# CPSW_CPSW3_08000000h register map
Vendor: Texas Instruments
Registers are 32-bit, read-write, reset 0x0 unless marked. A register's access mark holds for its fields unless they carry their own. Offsets are as the file gives them; [hi:lo] are bit positions; {n}, {i} and the like mark numbered series; 'fields as' and 'values as' point back to an identical list.

## cpsw3 (part 3 of 5)
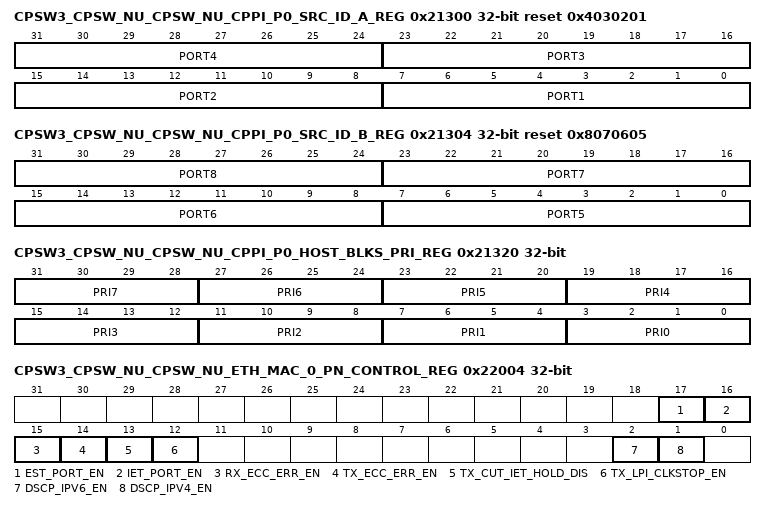
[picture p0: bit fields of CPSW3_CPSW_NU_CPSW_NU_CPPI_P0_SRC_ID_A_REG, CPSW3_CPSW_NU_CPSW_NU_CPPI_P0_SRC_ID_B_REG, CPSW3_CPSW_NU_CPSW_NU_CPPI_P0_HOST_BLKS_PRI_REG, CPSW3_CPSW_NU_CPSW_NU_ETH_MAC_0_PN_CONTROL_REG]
0x21300 CPSW3_CPSW_NU_CPSW_NU_CPPI_P0_SRC_ID_A_REG reset 0x4030201 — CPPI Port 0 CPPI Source ID A
  [8n-1:8n-8] PORT{n} (n=1..4) — Port {n} CPPI Info Word0 Source ID Value. This value is contained in the CPPI Info Word 0 SRC_ID field for packets received on port {n}.
0x21304 CPSW3_CPSW_NU_CPSW_NU_CPPI_P0_SRC_ID_B_REG reset 0x8070605 — CPPI Port 0 CPPI Source ID B
  [8n-33:8n-40] PORT{n} (n=5..8) — Port {n} CPPI Info Word0 Source ID Value. This value is contained in the CPPI Info Word 0 SRC_ID field for packets received on port {n}.
0x21320 CPSW3_CPSW_NU_CPSW_NU_CPPI_P0_HOST_BLKS_PRI_REG — CPPI Port 0 Host Blocks Priority
  [4n+3:4n] PRI{n} (n=0..7) — Priority {n} Host Blocks
0x22000 CPSW3_CPSW_NU_CPSW_NU_ETH_MAC_0_PN_RESERVED_REG ro — Reserved
0x22004 CPSW3_CPSW_NU_CPSW_NU_ETH_MAC_0_PN_CONTROL_REG — Enet Port N Control
  [17] EST_PORT_EN — EST Port Enable. 0h EST is disabled on the port1h EST is enabled on the port - Does not take effect until CPSW_CONTROL_REG[18] EST_ENABLE is set.
  [16] IET_PORT_EN — Intersperced Express Traffic (IET) Port Enable. 0h IET is disabled on the port1h IET is enabled on the port - Does not take effect until CPSW_CONTROL_REG[18] EST_ENABLE is set.
  [15] RX_ECC_ERR_EN — Port N receive ECC Error Enable. This bit must be set to enable receive ECC error operations
  [14] TX_ECC_ERR_EN — Port N transmit ECC Error Enable. This bit must be set to enable transmit ECC error operations
  [13] TX_CUT_IET_HOLD_DIS — Port N transmit IET hold due to cut-thru disable 0h Cut-thru packets to the port will cause premptable traffic to be prempted as early as possible minimizing cut-thru latency1h Cut-thru packets to the port will be prempted as usual by the express MAC
  [12] TX_LPI_CLKSTOP_EN — Transmit LPI Clock Stop Enable. When set this bit causes the transmit output clock (GMII_GMTCLK_O) to be stopped when the transmit LPI state is entered if EEE is enabled.
  [2] DSCP_IPV6_EN — IPV6 DSCP enable 0h IPV6 DSCP priority mapping is disabled1h IPV6 DSCP priority mapping is enabled
  [1] DSCP_IPV4_EN — IPV4 DSCP enable 0h IPV4 DSCP priority mapping is disabled1h IPV4 DSCP priority mapping is enabled
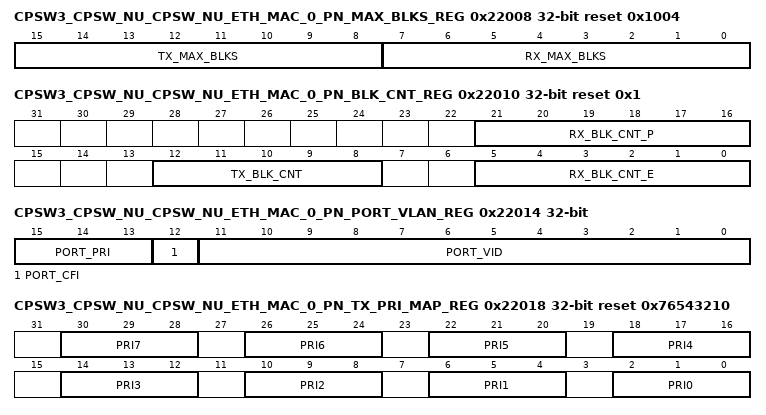
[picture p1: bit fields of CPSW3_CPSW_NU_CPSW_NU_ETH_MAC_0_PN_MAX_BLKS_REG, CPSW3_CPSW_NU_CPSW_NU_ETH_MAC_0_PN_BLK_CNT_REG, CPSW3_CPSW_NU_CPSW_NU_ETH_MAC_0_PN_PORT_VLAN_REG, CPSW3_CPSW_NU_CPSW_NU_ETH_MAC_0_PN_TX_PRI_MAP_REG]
0x22008 CPSW3_CPSW_NU_CPSW_NU_ETH_MAC_0_PN_MAX_BLKS_REG reset 0x1004 — Enet Port N FIFO Max Blocks
  [15:8] TX_MAX_BLKS — Transmit Max Blocks. The maximum number of blocks allowed on all transmit FIFO priorities combined. If (fifo_oneram = 1) then blocks should be moved from transmit to receive, when Fullduplex flow control is enabled (CPSW_PN_MAC_CONTROL_REG_k[0] FULLDUPLEX = 1h) to allow for flow control runout.
  [7:0] RX_MAX_BLKS — Receive Max Blocks. The maximum number of blocks allowed on the express and prempt receive FIFOs (transmit and receive FIFO's combined when fifo_oneram = 1)
0x22010 CPSW3_CPSW_NU_CPSW_NU_ETH_MAC_0_PN_BLK_CNT_REG ro reset 0x1 — Enet Port N FIFO Block Usage Count
  [21:16] RX_BLK_CNT_P — Receive Express Block Count Usage. This value is the number of blocks allocated to the port's FIFO prempt receive queue. No blocks are allocated until the CPSW_CONTROL_REG[17] IET_ENABLE is set.
  [12:8] TX_BLK_CNT — Transmit Block Count Usage. This value is the number of blocks allocated to the port's FIFO logical transmit queues.
  [5:0] RX_BLK_CNT_E — Receive Express Block Count Usage. This value is the number of blocks allocated to the port's FIFO express receive queue.
0x22014 CPSW3_CPSW_NU_CPSW_NU_ETH_MAC_0_PN_PORT_VLAN_REG — Enet Port N VLAN
  [15:13] PORT_PRI — Port VLAN Priority
  [12] PORT_CFI — Port CFI bit
  [11:0] PORT_VID — Port VLAN ID
0x22018 CPSW3_CPSW_NU_CPSW_NU_ETH_MAC_0_PN_TX_PRI_MAP_REG reset 0x76543210 — Enet Port N Tx Header Pri to Switch Pri Mapping
  [4n+2:4n] PRI{n} (n=0..7) — Priority {n}. A packet header priority of {n}h is given this switch queue pri.
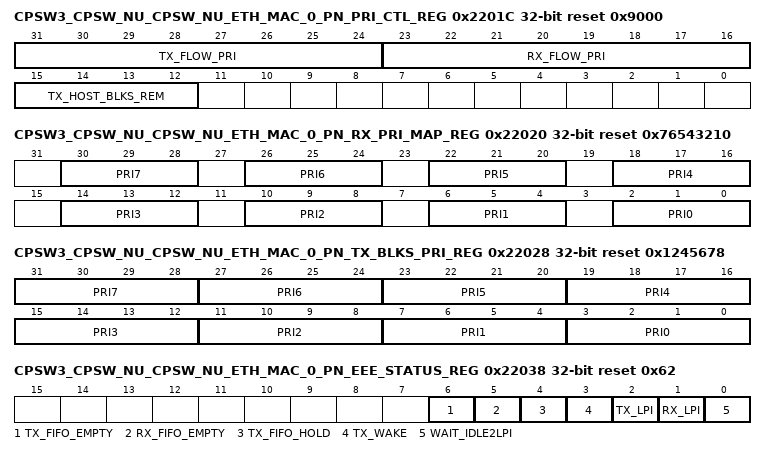
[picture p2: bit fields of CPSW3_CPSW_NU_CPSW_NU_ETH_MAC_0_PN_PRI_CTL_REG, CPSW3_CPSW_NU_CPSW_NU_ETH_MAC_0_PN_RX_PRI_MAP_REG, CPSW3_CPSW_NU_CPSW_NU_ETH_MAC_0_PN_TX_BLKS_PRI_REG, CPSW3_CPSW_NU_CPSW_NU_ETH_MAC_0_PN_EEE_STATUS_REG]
0x2201C CPSW3_CPSW_NU_CPSW_NU_ETH_MAC_0_PN_PRI_CTL_REG reset 0x9000 — Enet Port N Priority Control
  [31:24] TX_FLOW_PRI — Transmit Priority Based Flow Control Enable (per priority)
  [23:16] RX_FLOW_PRI — Receive Priority Based Flow Control Enable (per priority)
  [15:12] TX_HOST_BLKS_REM — Transmit FIFO Blocks that must be free before a non rate-limited CPPI Port 0 receive thread can begin sending a packet
0x22020 CPSW3_CPSW_NU_CPSW_NU_ETH_MAC_0_PN_RX_PRI_MAP_REG reset 0x76543210 — Enet Port N RX Pkt Pri to Header Pri Map
  [4n+2:4n] PRI{n} (n=0..7) — Priority {n}. A packet pri of {n}h is mapped (changed) to this header packet pri.
0x22024 CPSW3_CPSW_NU_CPSW_NU_ETH_MAC_0_PN_RX_MAXLEN_REG reset 0x5EE — Enet Port N Receive Frame Max Length
  [13:0] RX_MAXLEN — RX Maximum Frame Length. This field determines the maximum length of a received frame. The reset value is 1518 (dec). Frames with byte counts greater than the value in CPSW_PN_RX_MAXLEN_REG_k[13-0] RX_MAXLEN are long frames. Long frames with no errors are oversized frames. Long frames with CRC, code, or alignment error are jabber frames. The maximum value is 9604 (including VLAN).
0x22028 CPSW3_CPSW_NU_CPSW_NU_ETH_MAC_0_PN_TX_BLKS_PRI_REG reset 0x1245678 — Enet Port N Transmit Block Sub Per Priority
  [4n+3:4n] PRI{n} (n=0..7) — Priority {n} Port Transmit Blocks
0x22030 CPSW3_CPSW_NU_CPSW_NU_ETH_MAC_0_PN_IDLE2LPI_REG — Enet Port N EEE Idle to LPI counter
  [23:0] COUNT — EEE Idle to LPI counter load value
0x22034 CPSW3_CPSW_NU_CPSW_NU_ETH_MAC_0_PN_LPI2WAKE_REG — Enet Port N EEE LPI to wake counter
  [23:0] COUNT — EEE LPI to wake counter load value
0x22038 CPSW3_CPSW_NU_CPSW_NU_ETH_MAC_0_PN_EEE_STATUS_REG ro reset 0x62 — Enet Port N EEE status
  [6] TX_FIFO_EMPTY — Transmit FIFO (switch egress) is empty - contains no packets
  [5] RX_FIFO_EMPTY — Receive FIFO (switch ingress) is empty - contains no packets
  [4] TX_FIFO_HOLD — Transmit FIFO hold - asserted in the LPI state and during the LPI2WAKE count time
  [3] TX_WAKE — Transmit wakeup - asserted in the transmit LPI2WAKE count time
  [2] TX_LPI — Transmit LPI state - asserted when the port 0 transmit is in the LPI state
  [1] RX_LPI — Receive LPI state - asserted when the port 0 receive is in the LPI state
  [0] WAIT_IDLE2LPI — CPPI port 0 wait idle to LPI - asserted when port 0 is counting the IDLE2LPI time
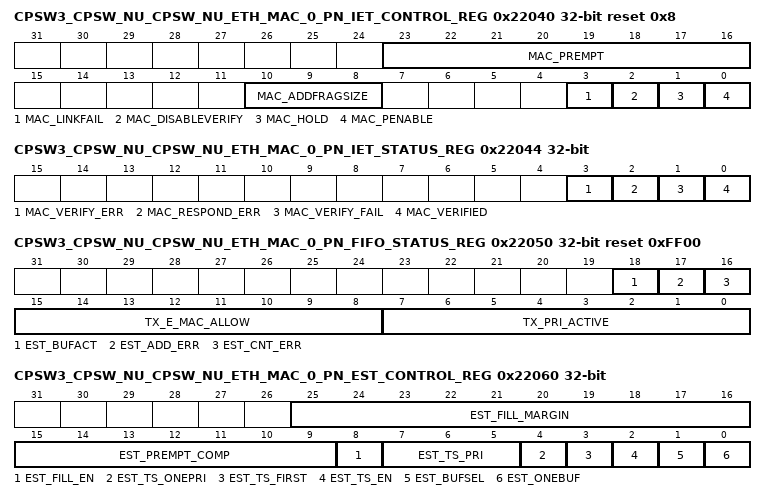
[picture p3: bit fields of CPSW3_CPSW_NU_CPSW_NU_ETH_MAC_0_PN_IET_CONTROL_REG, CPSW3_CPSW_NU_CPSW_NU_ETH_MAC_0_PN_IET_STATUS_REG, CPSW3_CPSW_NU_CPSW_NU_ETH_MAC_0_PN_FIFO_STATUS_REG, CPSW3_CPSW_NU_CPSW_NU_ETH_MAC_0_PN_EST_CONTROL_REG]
0x22040 CPSW3_CPSW_NU_CPSW_NU_ETH_MAC_0_PN_IET_CONTROL_REG reset 0x8 — Enet Port N IET Control
  [23:16] MAC_PREMPT — Mac Preempt Queue - Indicates which transmit FIFO queues are sent to the preempt MAC. Bit 0 indicates queue zero, bit 1 queue 1 and so on. Packets will be sent to the preempt MAC only when MAC_PENABLE is set, and when MAC_VERIFIED (from CPSW_PN_IET_STATUS_REG_k) or MAC_DISABLEVERIFY is set, and when IET_PORT_EN is set.
  [10:8] MAC_ADDFRAGSIZE — Mac Fragment Size - An integer in the range 0:7 indicating, as a multiple of 64, the minimum additional length for nonfinal mPackets. 0 641 1282 813 2564 3205 3846 4487 512
  [3] MAC_LINKFAIL — Mac Link Fail - Link Fail Indicator to reset the verify state machine. This bit is reset high. Verify and response frames will be sent/allowed when this bit is cleared.
  [2] MAC_DISABLEVERIFY — Mac Disable Verify - Disables verification on the port when set. If this bit is set then packets will be sent to the preempt Mac when MAC_PENABLE is set (This is a forced mode with no IET verification).
  [1] MAC_HOLD — Mac Hold - Hold Preemption on the port.
  [0] MAC_PENABLE — Mac Preemption Enable - Port Preemption Enable. This takes effect only when IET_PORT_EN is set.
0x22044 CPSW3_CPSW_NU_CPSW_NU_ETH_MAC_0_PN_IET_STATUS_REG ro — Enet Port N IET Status
  [3] MAC_VERIFY_ERR — Mac Received Verify Packet with Errors - Set when a verify packet with errors is received. Cleared when MAC_PENABLE is cleared to zero.
  [2] MAC_RESPOND_ERR — Mac Received Respond Packet with Errors - Set when a respond packet with errors is received. Cleared when MAC_PENABLE is cleared to zero.
  [1] MAC_VERIFY_FAIL — Mac Verification Failed - Indication that verification was unsuccessful.
  [0] MAC_VERIFIED — Mac Verified - Indication that verification was successful.
0x22048 CPSW3_CPSW_NU_CPSW_NU_ETH_MAC_0_PN_IET_VERIFY_REG reset 0x1312D0 — Enet Port N IET VERIFY
  [23:0] MAC_VERIFY_CNT — Mac Verify Timeout Count - The number of wireside clocks contained in the verify timeout counter. The default is 0x1312D0 (10ms at 125MHz in gig mode).
0x22050 CPSW3_CPSW_NU_CPSW_NU_ETH_MAC_0_PN_FIFO_STATUS_REG ro reset 0xFF00 — Enet Port N FIFO STATUS
  [18] EST_BUFACT — EST RAM active buffer. Indicates the active 64-word fetch buffer when CPSW_PN_EST_CONTROL_REG_k[0] EST_ONEBUF is cleared to zero. Indicates the fetch RAM address MSB when bit [0] EST_ONEBUF is set to one.
  [17] EST_ADD_ERR — EST Address Error. Indicates that the fetch RAM was read again after the previous maximum buffer address read (the previous fetch from the maximum address is reused).
  [16] EST_CNT_ERR — EST Fetch Count Error. Indicates that insufficient clocks were programmed into the fetch count and that another fetch was commanded before the previous fetch finished.
  [15:8] TX_E_MAC_ALLOW — EST transmit MAC allow. Bus that indicates the actual priorities assigned to the express queue (and inversely the priorities assigned to the prempt queue).
  [7:0] TX_PRI_ACTIVE — EST Transmit Priority Active. Bus that indicates which priorities have packets (non-empty) at the time of the register read.
0x22060 CPSW3_CPSW_NU_CPSW_NU_ETH_MAC_0_PN_EST_CONTROL_REG — Enet Port N EST CONTROL
  [25:16] EST_FILL_MARGIN — EST Fill Margin. Sets the fill margin required to ensure that the Ethernet wire is clear (including IPG) so that the timed EST express packet can egress at the required time. Setting this value too high will put an unnecessary gap on the wire. Setting this value too low will cause the express packet to egress at a time later than intended.
  [15:9] EST_PREMPT_COMP — EST Prempt Comparison Value. When the count in a zero allow is less than or equal to this value in bytes (times 8), prempt packets are cleared from the wire. This is the prempt clear margin value.
  [8] EST_FILL_EN — EST Fill Enable. Enable EST fill mode.
  [7:5] EST_TS_PRI — EST Timestamp Express Priority. Selects the express priority that timestamp(s) will be generated on when CPSW_PN_EST_CONTROL_REG_k[4] EST_TS_ONEPRI bit is set.
  [4] EST_TS_ONEPRI — EST Timestamp One Express Priority. When set, timestamp only enabled packets on the express priority selected by CPSW_PN_EST_CONTROL_REG_k[7-5] ST_TS_PRI bit field. When cleared to zero, express packet selection for timestamp is independent of priority.
  [3] EST_TS_FIRST — EST Timestamp First Express Packet only. Generate a timestamp only on the first selected express packet in each EST time interval when express timestamps are enabled. (If CPSW_PN_EST_CONTROL_REG_k[4] EST_TS_ONEPRI is also set then the timestamp is generated only on the first packet on CPSW_PN_EST_CONTROL_REG_k[7-5] ST_TS_PRI).
  [2] EST_TS_EN — EST Timestamp Enable. Enable express timestamps (when CPSW_CONTROL_REG[18] EST_ENABLE and CPSW_PN_CONTROL_REG_k[17] EST_PORT_EN bits are set).
  [1] EST_BUFSEL — EST Buffer Select. If CPSW_PN_EST_CONTROL_REG_k[0] EST_ONEBUF is cleared, this bit selects the upper (when set) or the lower (when cleared) 64-word fetch buffer. The actual fetch buffer used changes only at the start of the EST time interval and can be read in the CPSW_PN_FIFO_STATUS_REG_k register, bit [18] EST_BUFACT.
  [0] EST_ONEBUF — EST One Fetch Buffer. When set indicates that all 128 fetch words are used in one buffer. When cleared, indicates that the 128 fetch words are split into two 64-word fetch buffers. The CPSW_PN_EST_CONTROL_REG_k[1] EST_BUFSEL bit selects the buffer to be used when bit [0] EST_ONEBUF is cleared to zero.
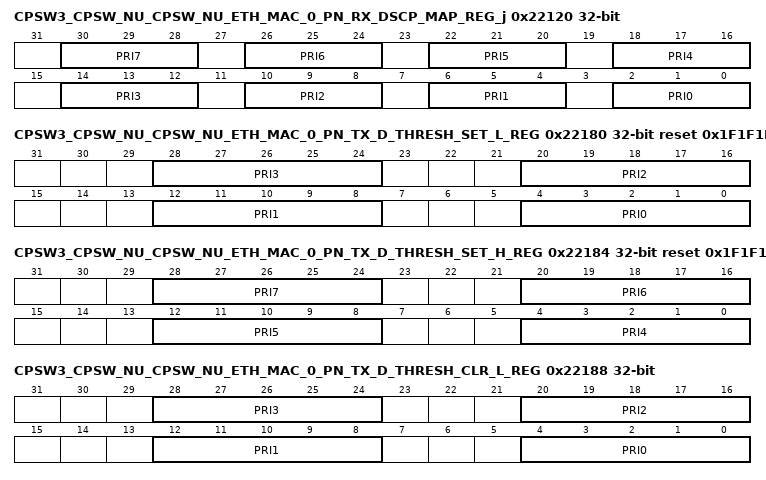
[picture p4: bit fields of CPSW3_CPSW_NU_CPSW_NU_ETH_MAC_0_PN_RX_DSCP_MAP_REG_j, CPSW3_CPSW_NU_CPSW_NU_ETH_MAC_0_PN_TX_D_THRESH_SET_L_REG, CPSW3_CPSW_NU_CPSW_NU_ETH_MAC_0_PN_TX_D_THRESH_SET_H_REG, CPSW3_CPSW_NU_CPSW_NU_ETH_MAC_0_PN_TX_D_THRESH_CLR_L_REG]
0x22120 CPSW3_CPSW_NU_CPSW_NU_ETH_MAC_0_PN_RX_DSCP_MAP_REG_j — Enet Port N Receive IPV4/IPV6 DSCP Map M
  [4n+2:4n] PRI{n} (n=0..7) — A DSCP IPV4/V6 packet TOS of N*8+{n} is mapped to this received priority
0x22140 CPSW3_CPSW_NU_CPSW_NU_ETH_MAC_0_PN_PRI_CIR_REG_j — Enet Port N Rx Priority P Committed Information Rate Value
  [27:0] PRI_CIR — Priority N committed information rate
0x22160 CPSW3_CPSW_NU_CPSW_NU_ETH_MAC_0_PN_PRI_EIR_REG_j — Enet Port N Rx Priority P Excess Informatoin Rate Value
  [27:0] PRI_EIR — Priority N Excess Information Rate count
0x22180 CPSW3_CPSW_NU_CPSW_NU_ETH_MAC_0_PN_TX_D_THRESH_SET_L_REG reset 0x1F1F1F1F — Enet Port N Tx PFC Destination Threshold Set Low
  [8n+4:8n] PRI{n} (n=0..3) — Port Priority Based Flow Control Threshold Set Value for Priority {n}
0x22184 CPSW3_CPSW_NU_CPSW_NU_ETH_MAC_0_PN_TX_D_THRESH_SET_H_REG reset 0x1F1F1F1F — Enet Port N Tx PFC Destination Threshold Set High
  [8n-28:8n-32] PRI{n} (n=4..7) — Port Priority Based Flow Control Threshold Set Value for Priority {n}
0x22188 CPSW3_CPSW_NU_CPSW_NU_ETH_MAC_0_PN_TX_D_THRESH_CLR_L_REG — Enet Port N Tx PFC Destination Threshold Clr Low
  [8n+4:8n] PRI{n} (n=0..3) — Port Priority Based Flow Control Threshold Clear Value for Priority {n}
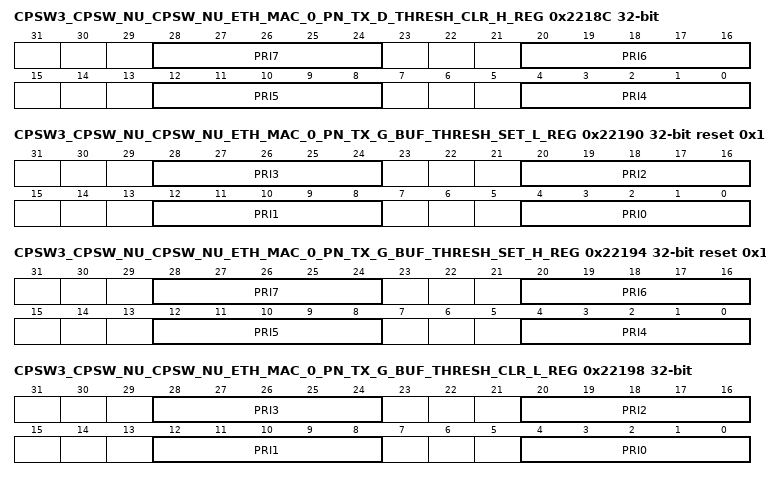
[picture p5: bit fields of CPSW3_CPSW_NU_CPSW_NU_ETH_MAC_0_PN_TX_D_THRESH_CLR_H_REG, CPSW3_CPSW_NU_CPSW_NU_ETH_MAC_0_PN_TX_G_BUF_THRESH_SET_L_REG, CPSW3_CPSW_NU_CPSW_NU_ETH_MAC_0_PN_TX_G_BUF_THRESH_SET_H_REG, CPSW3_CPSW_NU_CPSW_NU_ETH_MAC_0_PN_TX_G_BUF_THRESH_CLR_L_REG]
0x2218C CPSW3_CPSW_NU_CPSW_NU_ETH_MAC_0_PN_TX_D_THRESH_CLR_H_REG — Enet Port N Tx PFC Destination Threshold Clr High
  [8n-28:8n-32] PRI{n} (n=4..7) — Port Priority Based Flow Control Threshold Clear Value for Priority {n}
0x22190 CPSW3_CPSW_NU_CPSW_NU_ETH_MAC_0_PN_TX_G_BUF_THRESH_SET_L_REG reset 0x1F1F1F1F — Enet Port N Tx PFC Global Buffer Threshold Set Low
  fields as CPSW3_CPSW_NU_CPSW_NU_ETH_MAC_0_PN_TX_D_THRESH_SET_L_REG
0x22194 CPSW3_CPSW_NU_CPSW_NU_ETH_MAC_0_PN_TX_G_BUF_THRESH_SET_H_REG reset 0x1F1F1F1F — Enet Port N Tx PFC Global Buffer Threshold Set High
  fields as CPSW3_CPSW_NU_CPSW_NU_ETH_MAC_0_PN_TX_D_THRESH_SET_H_REG
0x22198 CPSW3_CPSW_NU_CPSW_NU_ETH_MAC_0_PN_TX_G_BUF_THRESH_CLR_L_REG — Enet Port N Tx PFC Global Buffer Threshold Clr Low
  fields as CPSW3_CPSW_NU_CPSW_NU_ETH_MAC_0_PN_TX_D_THRESH_CLR_L_REG
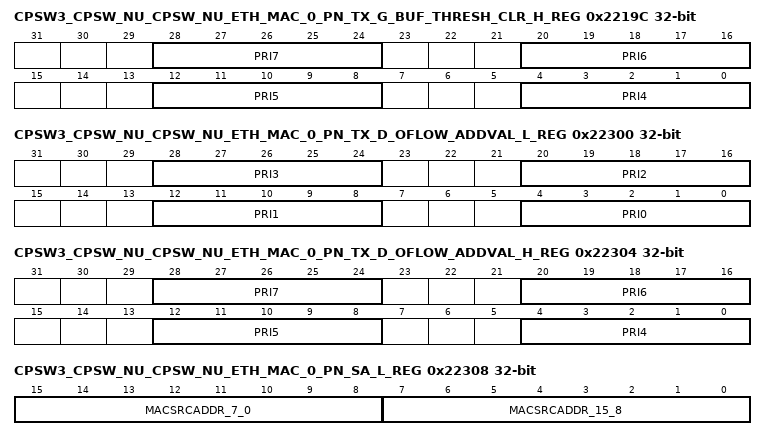
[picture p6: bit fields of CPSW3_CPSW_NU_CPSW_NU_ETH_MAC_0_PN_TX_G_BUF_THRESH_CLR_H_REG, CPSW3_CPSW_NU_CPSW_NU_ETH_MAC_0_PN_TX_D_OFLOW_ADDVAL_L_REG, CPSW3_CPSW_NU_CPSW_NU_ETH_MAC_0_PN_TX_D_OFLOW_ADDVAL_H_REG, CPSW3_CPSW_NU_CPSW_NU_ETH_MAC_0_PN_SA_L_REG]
0x2219C CPSW3_CPSW_NU_CPSW_NU_ETH_MAC_0_PN_TX_G_BUF_THRESH_CLR_H_REG — Enet Port N Tx PFC Global Buffer Threshold Clr High
  fields as CPSW3_CPSW_NU_CPSW_NU_ETH_MAC_0_PN_TX_D_THRESH_CLR_H_REG
0x22300 CPSW3_CPSW_NU_CPSW_NU_ETH_MAC_0_PN_TX_D_OFLOW_ADDVAL_L_REG — Enet Port N Tx Destination Out Flow Add Values Low
  [8n+4:8n] PRI{n} (n=0..3) — Port PFC Destination Based Out Flow Add Value for Priority {n}
0x22304 CPSW3_CPSW_NU_CPSW_NU_ETH_MAC_0_PN_TX_D_OFLOW_ADDVAL_H_REG — Enet Port N Tx Destination Out Flow Add Values High
  [8n-28:8n-32] PRI{n} (n=4..7) — Port PFC Destination Based Out Flow Add Value for Priority {n}
0x22308 CPSW3_CPSW_NU_CPSW_NU_ETH_MAC_0_PN_SA_L_REG — Enet Port N Tx Pause Frame Source Address Low
  [15:8] MACSRCADDR_7_0 — Source Address Lower 8 bits
  [7:0] MACSRCADDR_15_8 — Source Address bits 15:8
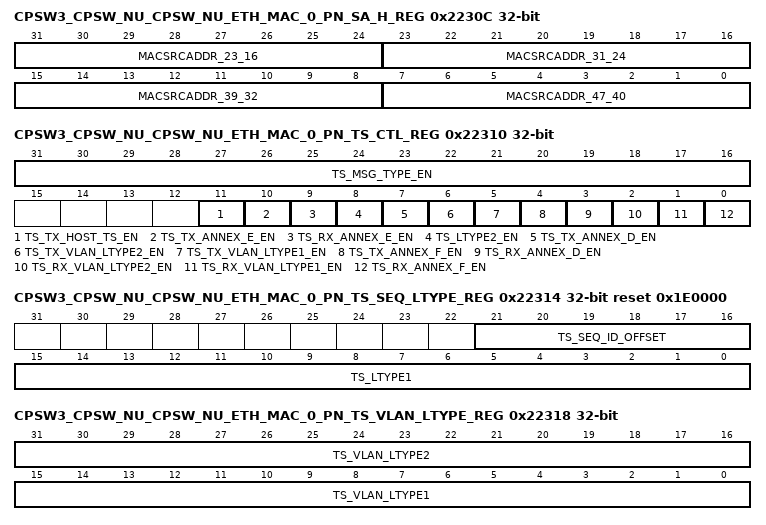
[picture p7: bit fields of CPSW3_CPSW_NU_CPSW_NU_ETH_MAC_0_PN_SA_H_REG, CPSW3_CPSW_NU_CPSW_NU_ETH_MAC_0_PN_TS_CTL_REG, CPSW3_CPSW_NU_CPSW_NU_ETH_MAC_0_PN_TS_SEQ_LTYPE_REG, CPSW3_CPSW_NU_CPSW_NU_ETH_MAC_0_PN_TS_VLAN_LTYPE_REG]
0x2230C CPSW3_CPSW_NU_CPSW_NU_ETH_MAC_0_PN_SA_H_REG — Enet Port N Tx Pause Frame Source Address High
  [31:24] MACSRCADDR_23_16 — Source Address bits 23:16
  [23:16] MACSRCADDR_31_24 — Source Address bits 31:24
  [15:8] MACSRCADDR_39_32 — Source Address bits 39:32
  [7:0] MACSRCADDR_47_40 — Source Address bits 47:40
0x22310 CPSW3_CPSW_NU_CPSW_NU_ETH_MAC_0_PN_TS_CTL_REG — Enet Port N Time Sync Control
  [31:16] TS_MSG_TYPE_EN — Time Sync Message Type Enable
  [11] TS_TX_HOST_TS_EN — Time Sync Transmit Host Time Stamp Enable
  [10] TS_TX_ANNEX_E_EN — Time Synce Transmit Annex E Enable
  [9] TS_RX_ANNEX_E_EN — Time Synce Receive Annex E Enable
  [8] TS_LTYPE2_EN — Time Sync LTYPE 2 enable transmit and receive
  [7] TS_TX_ANNEX_D_EN — Time Synce Transmit Annex D Enable
  [6] TS_TX_VLAN_LTYPE2_EN — Time Sync Transmit VLAN LTYPE 2 enable
  [5] TS_TX_VLAN_LTYPE1_EN — Time Sync Transmit VLAN LTYPE 1 enable
  [4] TS_TX_ANNEX_F_EN — Time Synce Transmit Annex F Enable
  [3] TS_RX_ANNEX_D_EN — Time Synce Receive Annex D Enable
  [2] TS_RX_VLAN_LTYPE2_EN — Time Sync Receive VLAN LTYPE 2 enable
  [1] TS_RX_VLAN_LTYPE1_EN — Time Sync Receive VLAN LTYPE 1 enable
  [0] TS_RX_ANNEX_F_EN — Time Synce Receive Annex F Enable
0x22314 CPSW3_CPSW_NU_CPSW_NU_ETH_MAC_0_PN_TS_SEQ_LTYPE_REG reset 0x1E0000 — Enet Port N Time Sync LTYPE (and SEQ_ID_OFFSET)
  [21:16] TS_SEQ_ID_OFFSET — Time Sync Sequence ID Offset. This is the number of octets that the sequence ID is offset in the TX and RX time sync message header. The minimum value is 6h.
  [15:0] TS_LTYPE1 — Time Sync LTYPE1. This is the port's time sync LTYPE1 value.
0x22318 CPSW3_CPSW_NU_CPSW_NU_ETH_MAC_0_PN_TS_VLAN_LTYPE_REG — Enet Port N Time Sync VLAN2 and VLAN2
  [31:16] TS_VLAN_LTYPE2 — Time Sync VLAN LTYPE2. This VLAN LTYPE value is used for the port TX and RX time sync decode.
  [15:0] TS_VLAN_LTYPE1 — Time Sync VLAN LTYPE1. This VLAN LTYPE value is used for the port TX and RX time sync decode.
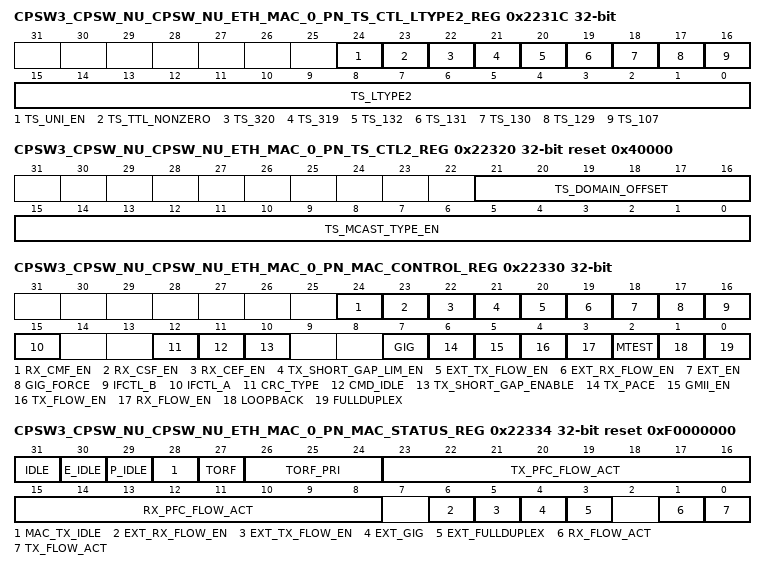
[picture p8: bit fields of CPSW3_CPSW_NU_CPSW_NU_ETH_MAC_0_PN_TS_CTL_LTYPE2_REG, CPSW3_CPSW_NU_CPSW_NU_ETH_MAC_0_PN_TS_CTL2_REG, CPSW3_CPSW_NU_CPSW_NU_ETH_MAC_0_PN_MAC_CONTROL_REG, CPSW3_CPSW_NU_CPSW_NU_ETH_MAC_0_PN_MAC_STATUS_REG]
0x2231C CPSW3_CPSW_NU_CPSW_NU_ETH_MAC_0_PN_TS_CTL_LTYPE2_REG — Enet Port N Time Sync Control and LTYPE 2
  [24] TS_UNI_EN — Time Sync Unicast Enable 0h Unicast disabled1h Unicast enabled
  [23] TS_TTL_NONZERO — Time Sync Time to Live Non-zero Enable 0h TTL must be 1h1h TTL may be any value
  [22] TS_320 — Time Sync Destination IP Address 320 Enable 0h Disabled1h Destination port number (decimal) 320 is enabled
  [21] TS_319 — Time Sync Destination IP Address 319 Enable 0h Disabled1h Destination port number (decimal) 319 is enabled
  [20] TS_132 — Time Sync Destination IP Address 132 Enable 0h Disabled1h Destination port number (decimal) 224.0.1.132 is enabled
  [19] TS_131 — Time Sync Destination IP Address 131 Enable 0h Disabled1h Destination port number (decimal) 224.0.1.131 is enabled
  [18] TS_130 — Time Sync Destination IP Address 130 Enable 0h Disabled1h Destination port number (decimal) 224.0.1.130 is enabled
  [17] TS_129 — Time Sync Destination IP Address 129 Enable 0h Disabled1h Destination port number (decimal) 224.0.1.129 is enabled
  [16] TS_107 — Time Sync Destination IP Address 107 Enable 0h Disabled1h Destination port number (decimal) 224.0.0.107 is enabled
  [15:0] TS_LTYPE2 — Time Sync LTYPE2. This is the time sync LTYPE1 value for port 1.
0x22320 CPSW3_CPSW_NU_CPSW_NU_ETH_MAC_0_PN_TS_CTL2_REG reset 0x40000 — Enet Port N Time Sync Control 2
  [21:16] TS_DOMAIN_OFFSET — Time Sync Domain Offset
  [15:0] TS_MCAST_TYPE_EN — Time Sync Multicast Destination Address Type Enable
0x22330 CPSW3_CPSW_NU_CPSW_NU_ETH_MAC_0_PN_MAC_CONTROL_REG — Enet Port N Mac Control
  [24] RX_CMF_EN — RX Copy MAC Control Frames Enable. Enables MAC control frames to be transferred to memory. MAC control frames are normally acted upon (if enabled), but not copied to memory. MAC control frames that are pause frames will be acted upon if enabled in the CPSW_PN_MAC_CONTROL_REG_k register, regardless of the value of [24] RX_CMF_EN bit. Frames transferred to memory due to [24] RX_CMF_EN will have the control bit set in their EOP buffer descriptor. 0h MAC control frames are filtered (but acted upon if enabled).1h MAC control frames are transferred to memory.
  [23] RX_CSF_EN — RX Copy Short Frames Enable. Enables frames or fragments shorter than 64 bytes to be copied to memory. Frames transferred to memory due to CPSW_PN_MAC_CONTROL_REG_k[23] RX_CSF_EN will have the fragment or undersized bit set in their receive footer. Fragments are short frames that contain CRC/align/code errors and undersized are short frames without errors. 0h Short frames are filtered.1h Short frames are transferred to memory.
  [22] RX_CEF_EN — RX Copy Error Frames Enable. Enables frames containing errors to be transferred to memory. The appropriate error bit will be set in the frame receive footer. Frames containing errors will be filtered when CPSW_PN_MAC_CONTROL_REG_k[22] RX_CEF_EN is not set. 0h Frames containing errors are filtered.1h Frames containing errors are transferred to memory.
  [21] TX_SHORT_GAP_LIM_EN — Transmit Short Gap Limit Enable When set this bit limits the number of short gap packets transmitted to 100ppm. The TX_SHORT_GAP_ENABLE bit must also be set. Each time a short gap packet is sent, a counter is loaded with 10,000 and decremented on each wireside clock. Another short gap packet will not be sent out until the counter decrements to zero. This mode is included to preclude the host from filling up the FIFO and sending every packet out with short gap which would violate the maximum number of packets per second allowed. This bit is used only with GMII (not XGMII).
  [20] EXT_TX_FLOW_EN — External Transmit Flow Control Enable. Enables the TX_FLOW_EN to be selected from the EXT_TX_FLOW_EN input signal and not from the [4] TX_FLOW_EN bit in CPSW_PN_MAC_CONTROL_REG_k register.
  [19] EXT_RX_FLOW_EN — External Receive Flow Control Enable. Enables the RX_FLOW_EN to be selected from the EXT_RX_FLOW_EN input signal and not from the CPSW_PN_MAC_CONTROL_REG_k[3] RX_FLOW_EN bit in this register.
  [18] EXT_EN — External Control Enable. Enables the fullduplex and gigabit mode to be selected from the FULLDUPLEX_IN and GIG_IN input signals and not from the [0] FULLDUPLEX and [7] GIG bits in the CPSW_PN_MAC_CONTROL_REG_k register. The [0] FULLDUPLEX bit reflects the actual fullduplex mode selected.
  [17] GIG_FORCE — Gigabit Mode Force. This bit is used to force the Ethernet Mac into gigabit mode if the input GMII_MTCLK has been stopped by the PHY.
  [16] IFCTL_B — Interface Control B. Intended as a general purpose output bit to be used to control external gaskets associated with the GMII (GMII to RGMII etc). 0h 10Mbps operation0h 100Mbps operation
  [15] IFCTL_A — Determines the RMII link speed. 0h 10Mbps operation0h 100Mbps operation
  [12] CRC_TYPE — Port CRC Type. 0h Ethernet CRC1h Castagnoli CRC
  [11] CMD_IDLE — Command Idle. 0h Idle not commanded1h Idle Commanded (read bit [31] IDLE in CPSW_PN_MAC_STATUS_REG_k register)
  [10] TX_SHORT_GAP_ENABLE — Transmit Short Gap Enable. 0h Transmit with a short IPG is disabled1h Transmit with a short IPG (when TX_SHORT_GAP input is asserted) is enabled.
  [7] GIG — Gigabit Mode. 0h 10/100 mode1h Gigabit mode (full duplex only) The GIG_OUT output is the value of this bit.
  [6] TX_PACE — Transmit Pacing Enable 0h Transmit Pacing Disabled1h Transmit Pacing Enabled
  [5] GMII_EN — GMII Enable. 0h GMII RX and TX held in reset.1h GMII RX and TX released from reset.
  [4] TX_FLOW_EN — Transmit Flow Control Enable. Determines if incoming pause frames are acted upon in full-duplex mode. Incoming pause frames are not acted upon in half-duplex mode regardless of this bit setting. The RX_MBP_ENABLE bits determine whether or not received pause frames are transferred to memory. 0h Transmit Flow Control Disabled. Full-duplex mode - Incoming pause frames are not acted upon.1h Transmit Flow Control Enabled. Full-duplex mode - Incoming pause frames are acted upon.
  [3] RX_FLOW_EN — Receive Flow Control Enable. 0h Receive Flow Control Disabled Half-duplex mode - No flow control generated collisions are sent. Full-duplex mode - No outgoing pause frames are sent.1h Receive Flow Control Enabled Half-duplex mode - Collisions are initiated when receive flow control is triggered. Full- duplex mode - Outgoing pause frames are sent when receive flow control is triggered.
  [2] MTEST — Manufacturing Test mode. This bit must be set to allow writes to the CPSW_PN_MAC_BOFFTEST_REG_k and CPSW_PN_MAC_RX_PAUSETIMER_REG_k registers.
  [1] LOOPBACK — Loop Back Mode. Loopback mode forces internal fullduplex mode regardless of whether the CPSW_PN_MAC_CONTROL_REG_k[0] FULLDUPLEX bit is set or not. The [1] LOOPBACK bit should be changed only when [5] GMII_EN is de-asserted. Loopback is used only with GMII (not XGMII). Loopback is not compatible with timestamp operations (CPTS). 0h Not looped back mode1h Loop Back mode enabled
  [0] FULLDUPLEX — Full Duplex mode. Gigabit mode forces fullduplex mode regardless of whether the [0] FULLDUPLEX bit is set or not. The FULLDUPLEX_OUT output is the value of this register bit 0h Half duplex mode1h Full duplex mode
0x22334 CPSW3_CPSW_NU_CPSW_NU_ETH_MAC_0_PN_MAC_STATUS_REG ro reset 0xF0000000 — Enet Port N Mac Status
  [31] IDLE — Enet IDLE. The Ethernet port (express and prempt) are in the Idle state (valid after an Idle command) 0h The port is not in the Idle state.1h The port is in the Idle state.
  [30] E_IDLE — Express MAC is Idle.
  [29] P_IDLE — Prempt MAC is Idle.
  [28] MAC_TX_IDLE — Mac Transmit Idle. Both Prempt and Express MAC Transmit are in Idle state. The transmit clock must be running for this to go idle.
  [27] TORF — Top of receive FIFO flow control trigger occurred. This bit is write one to clear.
  [26:24] TORF_PRI — The lowest priority that caused top of receive FIFO flow control trigger since the last write to clear. This field is write 7h to clear.
  [23:16] TX_PFC_FLOW_ACT — Transmit Priority Based Flow Control Active (priority 7 down to 0)
  [15:8] RX_PFC_FLOW_ACT — Receive Priority Based Flow Control Active (priority 7 down to 0)
  [6] EXT_RX_FLOW_EN — External Receive Flow Control Enable. This is the value of the CPSW_PN_MAC_CONTROL_REG_k[19] EXT_RX_FLOW_EN input bit.
  [5] EXT_TX_FLOW_EN — External Transmit Flow Control Enable. This is the value of the CPSW_PN_MAC_CONTROL_REG_k[20] EXT_TX_FLOW_EN input bit.
  [4] EXT_GIG — External GIG. This is the value of the [4] EXT_GIG input bit.
  [3] EXT_FULLDUPLEX — External Fullduplex. This is the value of the [3] EXT_FULLDUPLEX input bit.
  [1] RX_FLOW_ACT — Receive Flow Control Active. When asserted, indicates that receive flow control is enabled and triggered.
  [0] TX_FLOW_ACT — Transmit Flow Control Active. When asserted, this bit indicates that the pause time period is being observed for a received pause frame. No new transmissions will begin while this bit is asserted except for the transmission of pause frames. Any transmission in progress when this bit is asserted will complete.
0x22338 CPSW3_CPSW_NU_CPSW_NU_ETH_MAC_0_PN_MAC_SOFT_RESET_REG — Enet Port N Mac Soft Reset
  [0] SOFT_RESET — Software reset. Writing a 1h to this bit causes the Ethernet Mac logic to be reset. After writing a one to this bit, it may be polled to determine if the reset has occurred. If a 1h is read, the reset has not yet occurred. If a 0h is read then reset has occurred.
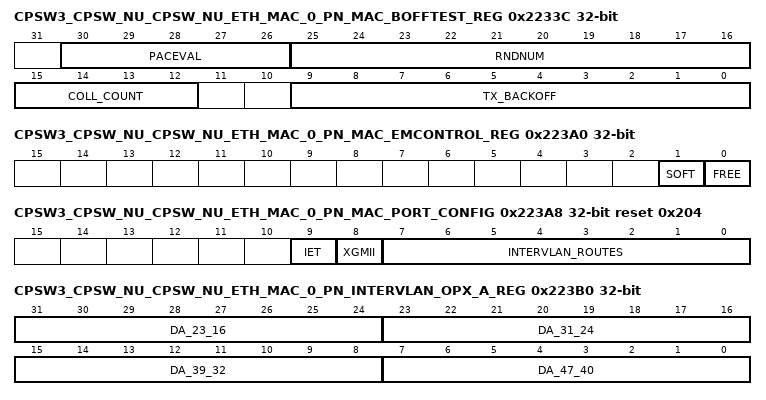
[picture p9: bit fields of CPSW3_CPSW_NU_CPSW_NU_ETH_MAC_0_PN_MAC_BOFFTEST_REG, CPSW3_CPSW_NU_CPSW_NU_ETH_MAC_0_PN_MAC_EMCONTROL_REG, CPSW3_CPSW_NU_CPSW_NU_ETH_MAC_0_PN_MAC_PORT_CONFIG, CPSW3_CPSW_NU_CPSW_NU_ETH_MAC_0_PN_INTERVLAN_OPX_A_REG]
0x2233C CPSW3_CPSW_NU_CPSW_NU_ETH_MAC_0_PN_MAC_BOFFTEST_REG access per field — Enet Port N Mac Backoff Test
  [30:26] PACEVAL rw — Pacing Current Value. A non-zero value in this field indicates that transmit pacing is active. A transmit frame collision or deferral causes paceval to loaded with decimal 31, good frame transmissions (with no collisions or deferrals) cause paceval to be decremented down to zero. When paceval is nonzero, the transmitter delays 4 IPGs between new frame transmissions after each successfully transmitted frame that had no deferrals or collisions. Transmit pacing helps reduce 'capture' effects improving overall network bandwidth.
  [25:16] RNDNUM rw — Backoff Random Number Generator. This field allows the Backoff Random Number Generator to be read (or written in test mode only). This field can be written only when CPSW_PN_MAC_CONTROL_REG_k[2] MTEST bit has previously been set. Reading this field returns the generator's current value. The value is reset to zero and begins counting on the clock after the de-assertion of reset.
  [15:12] COLL_COUNT ro — Collision Count.
  [9:0] TX_BACKOFF ro — Backoff Count. This field allows the current value of the backoff counter to be observed for test purposes. This field is loaded automatically according to the backoff algorithm, and is decremented by one for each slot time after the collision.
0x22340 CPSW3_CPSW_NU_CPSW_NU_ETH_MAC_0_PN_MAC_RX_PAUSETIMER_REG — Enet Port N 802.3 Receive Pause Timer
  [15:0] RX_PAUSETIMER — RX Pause Timer Value. This field allows the contents of the receive pause timer to be observed (and written in test mode). The receive pause timer is loaded with FF00h when the Ethernet port sends an outgoing pause frame (with pause time of FFFFh). The receive pause timer is decremented at slot time intervals. If the receive pause timer decrements to zero, then another outgoing pause frame will be sent and the load/decrement process will be repeated. This register is for 802.3 Based flow control and is not used for 802.1qbb Priority Based Flow Control (PFC).
0x22350 CPSW3_CPSW_NU_CPSW_NU_ETH_MAC_0_PN_MAC_RXN_PAUSETIMER_REG_j — Enet Port N PFC Priority P Rx Pause Timer
  [15:0] RX_PAUSETIMER — Rx Pause Timer Value. This field allows the contents of the receive pause timer to be observed (and written in test mode). The receive pause timer is loaded with FF00h when the Ethernet port sends an outgoing pause frame (with pause time of FFFFh). The receive pause timer is decremented at slot time intervals. If the receive pause timer decrements to zero, then another outgoing pause frame will be sent and the load/decrement process will be repeated. This register is for 802.1qbb Priority Based flow control (PFC)
0x22370 CPSW3_CPSW_NU_CPSW_NU_ETH_MAC_0_PN_MAC_TX_PAUSETIMER_REG — Enet Port N 802.3 Tx Pause Timer
  [15:0] TX_PAUSETIMER — 802.3 Tx Pause Timer Value. This field allows the contents of the transmit pause timer to be observed (and written in test mode). The transmit pause timer is loaded by a received (incoming) pause frame, and then decremented, at slottime intervals, down to zero at which time Ethernet Port transmit frames are again enabled. This register is for 802.3 Based flow control and is not used for 802.1qbb Priority Based Flow Control (PFC).
0x22380 CPSW3_CPSW_NU_CPSW_NU_ETH_MAC_0_PN_MAC_TXN_PAUSETIMER_REG_j — Enet Port N PFC Priority P Tx Pause Timer
  [15:0] TX_PAUSETIMER — PFC Tx 'y' Pause Timer Value. This field allows the contents of the transmit pause timer to be observed (and written in test mode). The transmit pause timer is loaded by a received (incoming) pause frame, and then decremented, at slottime intervals, down to zero at which time Ethernet Port transmit frames are again enabled. This register is for 802.1qbb Priority Based flow control (PFC)
0x223A0 CPSW3_CPSW_NU_CPSW_NU_ETH_MAC_0_PN_MAC_EMCONTROL_REG — Enet Port N Emulation Control
  [1] SOFT — Emulation Soft Bit
  [0] FREE — Emulation Free Bit
0x223A4 CPSW3_CPSW_NU_CPSW_NU_ETH_MAC_0_PN_MAC_TX_GAP_REG reset 0xC — Enet Port N Tx Inter Packet Gap
  [15:0] TX_GAP — Transmit Inter-Packet Gap GMII modes - This is the default gap value and only bits [8-0] are used. This can be increased from 12 to increase the gap between packets. XGMII mode - In 10 Gigabit mode this is the short gap rate and should be changed to 5000 (1388h) to get approximately 200ppm faster when short gap is triggered and enabled.
0x223A8 CPSW3_CPSW_NU_CPSW_NU_ETH_MAC_0_PN_MAC_PORT_CONFIG ro reset 0x204 — Enet Port N Port Configuration
  [9] IET — Intersperced Express Traffic (IET) is supported on this port when read high.
  [8] XGMII — XGMII is supported on this port when set.
  [7:0] INTERVLAN_ROUTES — This is the number of InterVLAN routes supported on this port (egress).
0x223AC CPSW3_CPSW_NU_CPSW_NU_ETH_MAC_0_PN_INTERVLAN_OPX_POINTER_REG — Enet Port N Tx Egress InterVLAN Operation Pointer
  [2:0] POINTER — InterVLAN location pointer: This field points to the InterVLAN location that will be read/written by accesses to Enet_Pn_InterVLANx_A/B.
0x223B0 CPSW3_CPSW_NU_CPSW_NU_ETH_MAC_0_PN_INTERVLAN_OPX_A_REG — Enet Port N Tx Egress InterVLAN A
  [31:24] DA_23_16 — Destination Address bits 23:16 - DA byte 4 on wire
  [23:16] DA_31_24 — Destination Address bits 31:24 - DA byte 3 on wire
  [15:8] DA_39_32 — Destination Address bits 39:32 - DA byte 2 on wire
  [7:0] DA_47_40 — Destination Address bits 47:40 - DA byte 1 on wire
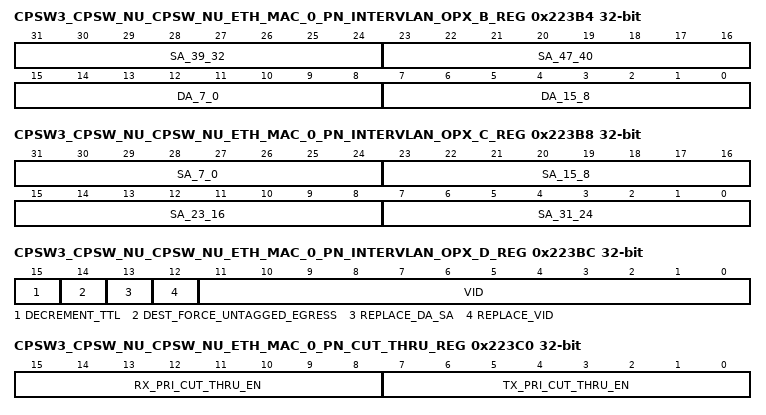
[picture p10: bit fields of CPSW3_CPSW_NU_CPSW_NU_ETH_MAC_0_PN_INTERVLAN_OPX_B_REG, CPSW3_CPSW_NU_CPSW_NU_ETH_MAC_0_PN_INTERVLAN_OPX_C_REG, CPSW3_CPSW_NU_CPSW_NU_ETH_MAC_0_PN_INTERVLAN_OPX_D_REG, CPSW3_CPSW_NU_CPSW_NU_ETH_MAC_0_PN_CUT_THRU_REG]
0x223B4 CPSW3_CPSW_NU_CPSW_NU_ETH_MAC_0_PN_INTERVLAN_OPX_B_REG — Enet Port N Tx Egress InterVLAN B
  [31:24] SA_39_32 — Source Address bits 39:32 - SA byte 2 on wire
  [23:16] SA_47_40 — Source Address bits 47:40 - SA byte 1 on wire
  [15:8] DA_7_0 — Destination Address bits 7:0 - DA byte 6 on wire
  [7:0] DA_15_8 — Destination Address bits 15:8 - DA byte 5 on wire
0x223B8 CPSW3_CPSW_NU_CPSW_NU_ETH_MAC_0_PN_INTERVLAN_OPX_C_REG — Enet Port N Tx Egress InterVLAN C
  [31:24] SA_7_0 — Source Address bits 7:0 - DA byte 6 on wire
  [23:16] SA_15_8 — Source Address bits 15:8 - DA byte 5 on wire
  [15:8] SA_23_16 — Source Address bits 23:16 - DA byte 4 on wire
  [7:0] SA_31_24 — Source Address bits 31:24 - DA byte 3 on wire
0x223BC CPSW3_CPSW_NU_CPSW_NU_ETH_MAC_0_PN_INTERVLAN_OPX_D_REG — Enet Port N Tx Egress InterVLAN D
  [15] DECREMENT_TTL — Decrement Time To Live: When set, the Time To Live (TTL) field in the header is decremented.
  [14] DEST_FORCE_UNTAGGED_EGRESS — Destination VLAN Force Untagged Egress: When set, this bit indicates that the VLAN should be removed on egress for the routed packet.
  [13] REPLACE_DA_SA — Replace Destination Address and Source Address: When set this bit indicates that the routed packet destination address should be replaced by da[47:0] and the source address should be replaced by sa[47:0].
  [12] REPLACE_VID — Replace VLAN ID: When set this bit indicates that the VLAN ID should be replaced for the routed packet.
  [11:0] VID — VLAN ID
0x223C0 CPSW3_CPSW_NU_CPSW_NU_ETH_MAC_0_PN_CUT_THRU_REG — Enet Port N Cut Thru Priority Enable
  [15:8] RX_PRI_CUT_THRU_EN — Receive Cut Thru Priority Enable
  [7:0] TX_PRI_CUT_THRU_EN — Transmit Cut Thru Priority Enable
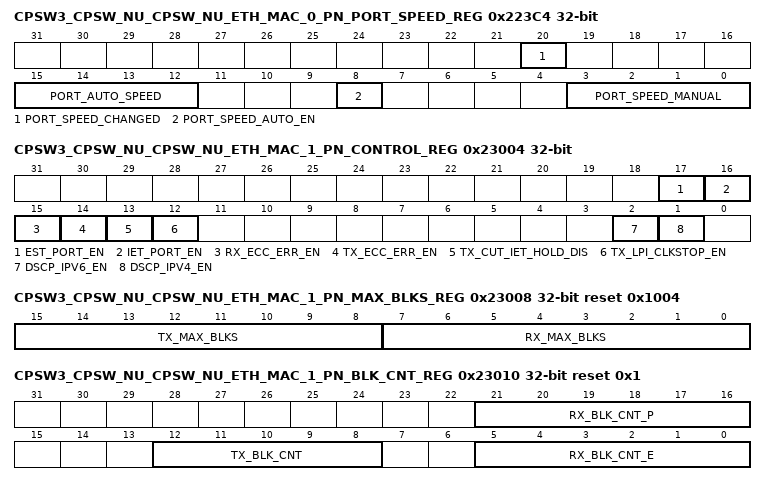
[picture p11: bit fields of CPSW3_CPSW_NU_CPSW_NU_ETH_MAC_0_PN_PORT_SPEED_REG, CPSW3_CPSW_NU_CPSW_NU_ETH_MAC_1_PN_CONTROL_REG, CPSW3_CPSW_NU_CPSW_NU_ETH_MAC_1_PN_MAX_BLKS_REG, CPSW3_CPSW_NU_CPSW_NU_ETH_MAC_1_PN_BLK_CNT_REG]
0x223C4 CPSW3_CPSW_NU_CPSW_NU_ETH_MAC_0_PN_PORT_SPEED_REG access per field — Enet Port Speed
  [20] PORT_SPEED_CHANGED ro
  [15:12] PORT_AUTO_SPEED ro — Detected Auto Speed
  [8] PORT_SPEED_AUTO_EN rw — Automatic Port Speed Enable
  [3:0] PORT_SPEED_MANUAL rw — Manual Port Speed
0x23000 CPSW3_CPSW_NU_CPSW_NU_ETH_MAC_1_PN_RESERVED_REG ro — Reserved
0x23004 CPSW3_CPSW_NU_CPSW_NU_ETH_MAC_1_PN_CONTROL_REG — Enet Port N Control
  fields as CPSW3_CPSW_NU_CPSW_NU_ETH_MAC_0_PN_CONTROL_REG
0x23008 CPSW3_CPSW_NU_CPSW_NU_ETH_MAC_1_PN_MAX_BLKS_REG reset 0x1004 — Enet Port N FIFO Max Blocks
  fields as CPSW3_CPSW_NU_CPSW_NU_ETH_MAC_0_PN_MAX_BLKS_REG
0x23010 CPSW3_CPSW_NU_CPSW_NU_ETH_MAC_1_PN_BLK_CNT_REG ro reset 0x1 — Enet Port N FIFO Block Usage Count
  fields as CPSW3_CPSW_NU_CPSW_NU_ETH_MAC_0_PN_BLK_CNT_REG
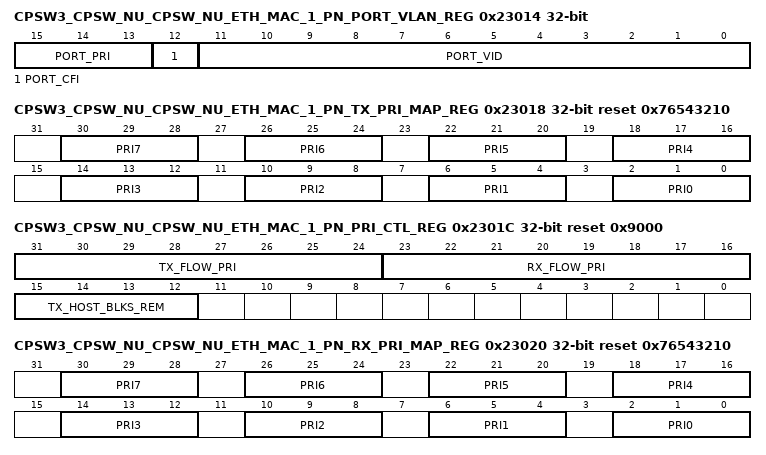
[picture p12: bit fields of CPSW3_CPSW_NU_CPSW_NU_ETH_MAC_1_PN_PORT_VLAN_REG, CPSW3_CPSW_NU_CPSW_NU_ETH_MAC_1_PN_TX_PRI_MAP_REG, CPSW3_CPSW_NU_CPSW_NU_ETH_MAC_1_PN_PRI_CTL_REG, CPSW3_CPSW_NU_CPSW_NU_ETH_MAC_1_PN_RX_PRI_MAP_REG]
0x23014 CPSW3_CPSW_NU_CPSW_NU_ETH_MAC_1_PN_PORT_VLAN_REG — Enet Port N VLAN
  fields as CPSW3_CPSW_NU_CPSW_NU_ETH_MAC_0_PN_PORT_VLAN_REG
0x23018 CPSW3_CPSW_NU_CPSW_NU_ETH_MAC_1_PN_TX_PRI_MAP_REG reset 0x76543210 — Enet Port N Tx Header Pri to Switch Pri Mapping
  fields as CPSW3_CPSW_NU_CPSW_NU_ETH_MAC_0_PN_TX_PRI_MAP_REG
0x2301C CPSW3_CPSW_NU_CPSW_NU_ETH_MAC_1_PN_PRI_CTL_REG reset 0x9000 — Enet Port N Priority Control
  fields as CPSW3_CPSW_NU_CPSW_NU_ETH_MAC_0_PN_PRI_CTL_REG
0x23020 CPSW3_CPSW_NU_CPSW_NU_ETH_MAC_1_PN_RX_PRI_MAP_REG reset 0x76543210 — Enet Port N RX Pkt Pri to Header Pri Map
  fields as CPSW3_CPSW_NU_CPSW_NU_ETH_MAC_0_PN_RX_PRI_MAP_REG
